# STM32F378xx register map
File version: 1.0
Registers are 32-bit, read-write, reset 0x0 unless marked. A register's access mark holds for its fields unless they carry their own. Offsets are from the block's base; [hi:lo] are bit positions; {n}, {i} and the like mark numbered series; 'fields as' and 'values as' point back to an identical list.

## DMA1
Base 0x40020000
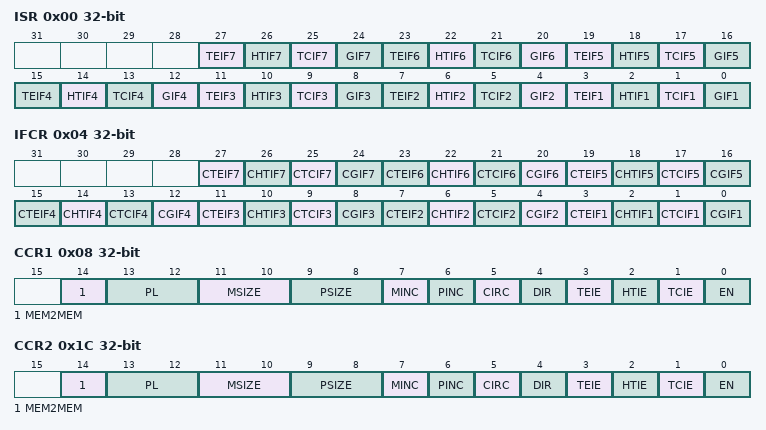
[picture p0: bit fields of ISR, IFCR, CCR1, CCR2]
0x00 ISR — DMA interrupt status register
  [4n-1] TEIF{n} (n=1..7) — Channel {n} Transfer Error flag
  [4n-2] HTIF{n} (n=1..7) — Channel {n} Half Transfer flag
  [4n-3] TCIF{n} (n=1..7) — Channel {n} Transfer Complete flag
  [4n-4] GIF{n} (n=1..7) — Channel {n} Global interrupt flag
0x04 IFCR — DMA interrupt flag clear register
  [4n-1] CTEIF{n} (n=1..7) — Channel {n} Transfer Error clear
  [4n-2] CHTIF{n} (n=1..7) — Channel {n} Half Transfer clear
  [4n-3] CTCIF{n} (n=1..7) — Channel {n} Transfer Complete clear
  [4n-4] CGIF{n} (n=1..7) — Channel {n} Global interrupt clear
0x08 CCR1 — DMA channel x configuration register
  [14] MEM2MEM — Memory to memory mode
  [13:12] PL — PL[1:0] bits(Channel Priority level)
  [11:10] MSIZE — MSIZE[1:0] bits (Memory size)
  [9:8] PSIZE — PSIZE[1:0] bits (Peripheral size)
  [7] MINC — Memory increment mode
  [6] PINC — Peripheral increment mode
  [5] CIRC — Circular mode
  [4] DIR — Data transfer direction
  [3] TEIE — Transfer error interrupt enable
  [2] HTIE — Half Transfer interrupt enable
  [1] TCIE — Transfer complete interrupt enable
  [0] EN — Channel enable
0x0C CNDTR1 — DMA channel x number of data register
  [15:0] NDT — Number of data to Transfer
0x10 CPAR1 — DMA channel x peripheral address register
  [31:0] PA — Peripheral Address
{0x0+0x14*i} CMAR{i} (i=1..7) — DMA channel x memory address register
  [31:0] MA — Memory Address
0x1C CCR2 — DMA channel x configuration register
  fields as CCR1
0x20 CNDTR2 — DMA channel x number of data register
  [15:0] NDT — Number of data to Transfer
0x24 CPAR2 — DMA channel x peripheral address register
  [31:0] PA — Peripheral Address
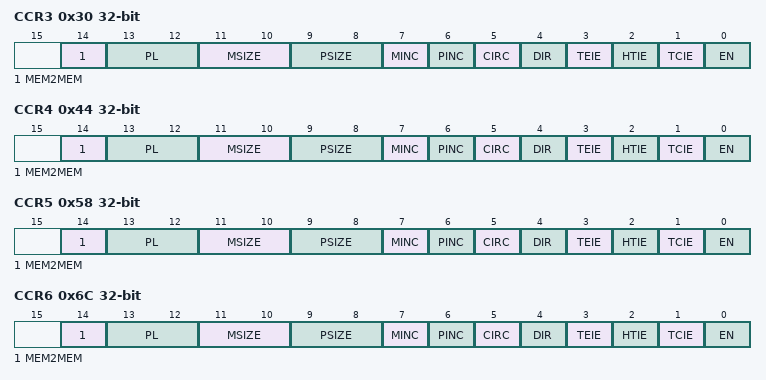
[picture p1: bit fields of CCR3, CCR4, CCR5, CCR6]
0x30 CCR3 — DMA channel x configuration register
  fields as CCR1
0x34 CNDTR3 — DMA channel x number of data register
  [15:0] NDT — Number of data to Transfer
0x38 CPAR3 — DMA channel x peripheral address register
  [31:0] PA — Peripheral Address
0x44 CCR4 — DMA channel x configuration register
  fields as CCR1
0x48 CNDTR4 — DMA channel x number of data register
  [15:0] NDT — Number of data to Transfer
0x4C CPAR4 — DMA channel x peripheral address register
  [31:0] PA — Peripheral Address
0x58 CCR5 — DMA channel x configuration register
  fields as CCR1
0x5C CNDTR5 — DMA channel x number of data register
  [15:0] NDT — Number of data to Transfer
0x60 CPAR5 — DMA channel x peripheral address register
  [31:0] PA — Peripheral Address
0x6C CCR6 — DMA channel x configuration register
  fields as CCR1
0x70 CNDTR6 — DMA channel x number of data register
  [15:0] NDT — Number of data to Transfer
0x74 CPAR6 — DMA channel x peripheral address register
  [31:0] PA — Peripheral Address
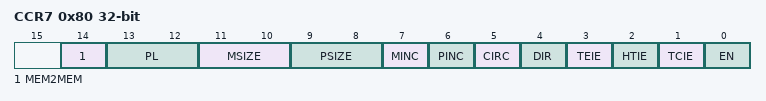
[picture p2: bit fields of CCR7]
0x80 CCR7 — DMA channel x configuration register
  fields as CCR1
0x84 CNDTR7 — DMA channel x number of data register
  [15:0] NDT — Number of data to Transfer
0x88 CPAR7 — DMA channel x peripheral address register
  [31:0] PA — Peripheral Address

## DMA2
Base 0x40020400
Registers as DMA1, without CCR6, CNDTR6, CPAR6, CMAR6, CCR7, CNDTR7, CPAR7, CMAR7.

## FLASH — FLASH Registers
Base 0x40022000
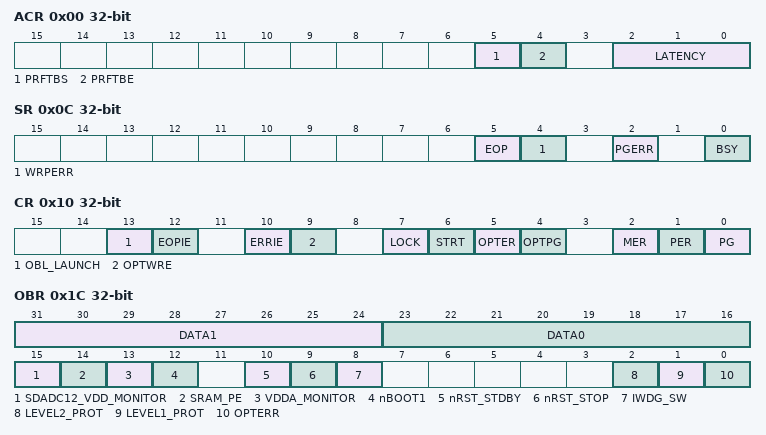
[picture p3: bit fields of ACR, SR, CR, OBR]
0x00 ACR — FLASH access control register
  [5] PRFTBS — Prefetch Buffer Status
  [4] PRFTBE — Prefetch Buffer Enable
  [2:0] LATENCY — LATENCY[2:0] bits (Latency)
    0=FLASH Zero Latency cycle; 1=FLASH One Latency cycle; 2=FLASH Two Latency cycles
0x04 KEYR — FLASH key register
  [31:0] FKEYR — FPEC Key
0x08 OPTKEYR — FLASH option key register
  [31:0] OPTKEYR — Option Byte Key
0x0C SR — FLASH status register
  [5] EOP — End of operation
  [4] WRPERR — Write Protection Error
  [2] PGERR — Programming Error
  [0] BSY — Busy
0x10 CR — FLASH control register
  [13] OBL_LAUNCH — OptionBytes Loader Launch
  [12] EOPIE — End of operation interrupt enable
  [10] ERRIE — Error Interrupt Enable
  [9] OPTWRE — Option Bytes Write Enable
  [7] LOCK
  [6] STRT — Start
  [5] OPTER — Option Byte Erase
  [4] OPTPG — Option Byte Programming
  [2] MER — Mass Erase
  [1] PER — Page Erase
  [0] PG — Programming
0x14 AR — FLASH address register
  [31:0] FAR — Flash Address
0x1C OBR — FLASH Option byte register
  [31:24] DATA1
  [23:16] DATA0
  [15] SDADC12_VDD_MONITOR
  [14] SRAM_PE
  [13] VDDA_MONITOR
  [12] nBOOT1
  [10] nRST_STDBY
  [9] nRST_STOP
  [8] IWDG_SW
  [2] LEVEL2_PROT — Level 2 Read protection status
  [1] LEVEL1_PROT — Level 1 Read protection status
  [0] OPTERR — Option Byte Error
0x20 WRPR — FLASH Write register
  [31:0] WRP — Write Protect
